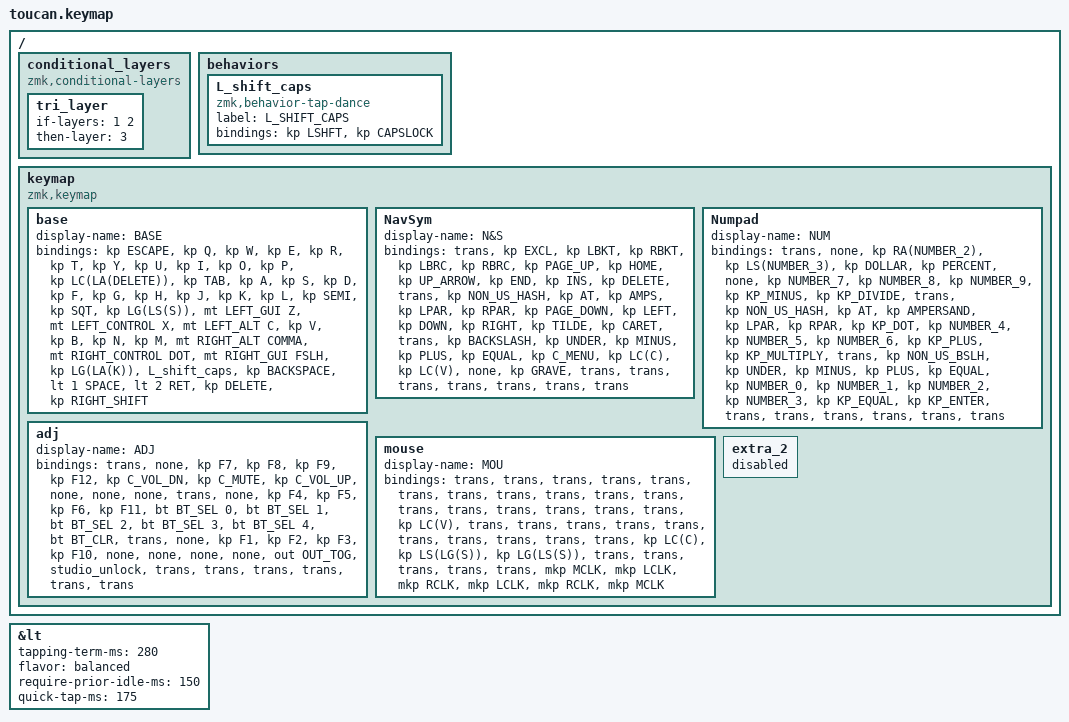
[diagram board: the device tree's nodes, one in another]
#include <behaviors.dtsi>
#include <dt-bindings/zmk/bt.h>
#include <dt-bindings/zmk/keys.h>
#include <dt-bindings/zmk/outputs.h>
#include <dt-bindings/zmk/pointing.h>

#define BASE 0
#define NAV  1
#define SYM  2
#define ADJ  3

&lt {
    tapping-term-ms = <280>;
    flavor = "balanced";
    require-prior-idle-ms = <150>;
    quick-tap-ms = <175>;
};

/ {
    conditional_layers {
        compatible = "zmk,conditional-layers";

        tri_layer {
            if-layers = <1 2>;
            then-layer = <3>;
        };
    };

    behaviors {
        L_shift_caps: L_shift_caps {
            compatible = "zmk,behavior-tap-dance";
            label = "L_SHIFT_CAPS";
            #binding-cells = <0>;
            bindings = <&kp LSHFT>, <&kp CAPSLOCK>;
        };
    };

    keymap {
        compatible = "zmk,keymap";

        base {
            display-name = "BASE";
            bindings = <
&kp ESCAPE  &kp Q  &kp W  &kp E  &kp R  &kp T  &kp Y  &kp U  &kp I  &kp O  &kp P  &kp LC(LA(DELETE))  &kp TAB  &kp A  &kp S  &kp D  &kp F  &kp G  &kp H  &kp J  &kp K  &kp L  &kp SEMI  &kp SQT  &kp LG(LS(S))  &mt LEFT_GUI Z  &mt LEFT_CONTROL X  &mt LEFT_ALT C  &kp V  &kp B  &kp N  &kp M  &mt RIGHT_ALT COMMA  &mt RIGHT_CONTROL DOT  &mt RIGHT_GUI FSLH  &kp LG(LA(K))  &L_shift_caps  &kp BACKSPACE  &lt 1 SPACE  &lt 2 RET  &kp DELETE  &kp RIGHT_SHIFT
            >;
        };

        NavSym {
            display-name = "N&S";
            bindings = <
&trans  &kp EXCL  &kp LBKT  &kp RBKT  &kp LBRC  &kp RBRC  &kp PAGE_UP  &kp HOME  &kp UP_ARROW  &kp END  &kp INS  &kp DELETE  &trans  &kp NON_US_HASH  &kp AT  &kp AMPS  &kp LPAR  &kp RPAR  &kp PAGE_DOWN  &kp LEFT  &kp DOWN  &kp RIGHT  &kp TILDE  &kp CARET  &trans  &kp BACKSLASH  &kp UNDER  &kp MINUS  &kp PLUS  &kp EQUAL  &kp C_MENU  &kp LC(C)  &kp LC(V)  &none  &kp GRAVE  &trans  &trans  &trans  &trans  &trans  &trans  &trans
            >;
        };

        Numpad {
            display-name = "NUM";
            bindings = <
&trans  &none  &kp RA(NUMBER_2)  &kp LS(NUMBER_3)  &kp DOLLAR  &kp PERCENT  &none  &kp NUMBER_7  &kp NUMBER_8  &kp NUMBER_9  &kp KP_MINUS  &kp KP_DIVIDE  &trans  &kp NON_US_HASH  &kp AT  &kp AMPERSAND  &kp LPAR  &kp RPAR  &kp KP_DOT  &kp NUMBER_4  &kp NUMBER_5  &kp NUMBER_6  &kp KP_PLUS  &kp KP_MULTIPLY  &trans  &kp NON_US_BSLH  &kp UNDER  &kp MINUS  &kp PLUS  &kp EQUAL  &kp NUMBER_0  &kp NUMBER_1  &kp NUMBER_2  &kp NUMBER_3  &kp KP_EQUAL  &kp KP_ENTER  &trans  &trans  &trans  &trans  &trans  &trans
            >;
        };

        adj {
            display-name = "ADJ";
            bindings = <
&trans  &none  &kp F7  &kp F8  &kp F9  &kp F12  &kp C_VOL_DN  &kp C_MUTE  &kp C_VOL_UP  &none  &none  &none  &trans  &none  &kp F4  &kp F5  &kp F6  &kp F11  &bt BT_SEL 0  &bt BT_SEL 1  &bt BT_SEL 2  &bt BT_SEL 3  &bt BT_SEL 4  &bt BT_CLR  &trans  &none  &kp F1  &kp F2  &kp F3  &kp F10  &none  &none  &none  &none  &out OUT_TOG  &studio_unlock  &trans  &trans  &trans  &trans  &trans  &trans
            >;
        };

        mouse {
            display-name = "MOU";
            bindings = <
&trans  &trans  &trans  &trans  &trans  &trans  &trans  &trans  &trans  &trans  &trans  &trans  &trans  &trans  &trans  &trans  &trans  &kp LC(V)  &trans  &trans  &trans  &trans  &trans  &trans  &trans  &trans  &trans  &trans  &kp LC(C)  &kp LS(LG(S))  &kp LG(LS(S))  &trans  &trans  &trans  &trans  &trans  &mkp MCLK  &mkp LCLK  &mkp RCLK  &mkp LCLK  &mkp RCLK  &mkp MCLK
            >;
        };

        extra_2 { status = "reserved"; };
    };
};
